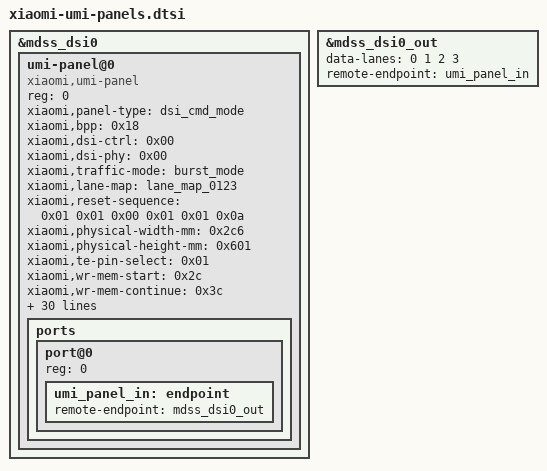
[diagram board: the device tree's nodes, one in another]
// SPDX-License-Identifier: BSD-3-Clause
/*
 * xiaomi-umi-panels.dtsi — 自动生成，别手改
 *   生成: python tools/gen-panel-dts.py dump/panels \
 *             -o dts/xiaomi-umi-panels.dtsi --enable qcom,mdss_dsi_j2_mp_42_02_0b_dsc_cmd
 *
 * 数据全部来自设备自己的下游 DTB。驱动只认 "xiaomi,umi-panel"，
 * 时序 / init 序列 / DSC 参数都从 DT 读 —— 换屏只改 --enable，不用改驱动。
 *
 * ★ 面板节点必须是 &mdss_dsi0 的子节点（reg = <0> 选虚拟通道 0），
 *   否则 mipi_dsi 不会为它创建 mipi_dsi_device，驱动根本不会 probe。
 * ★ 22 个变体不要同时塞进来：同一父节点下只能有一个 panel@0。
 *   换屏 = 重新跑一次生成器 + dtb-only.sh（1 分钟，不用重编内核）。
 */

&mdss_dsi0 {
	umi-panel@0 {
		compatible = "xiaomi,umi-panel";
		reg = <0>;
		status = "okay";
		/* xiaomi,no-init; */
		xiaomi,panel-type = "dsi_cmd_mode";
		xiaomi,bpp = <0x18>;
		xiaomi,dsi-ctrl = <0x00>;
		xiaomi,dsi-phy = <0x00>;
		xiaomi,traffic-mode = "burst_mode";
		xiaomi,lane-map = "lane_map_0123";
		xiaomi,reset-sequence = <0x01 0x01 0x00 0x01 0x01 0x0a>;
		xiaomi,physical-width-mm = <0x2c6>;
		xiaomi,physical-height-mm = <0x601>;
		xiaomi,te-pin-select = <0x01>;
		xiaomi,wr-mem-start = <0x2c>;
		xiaomi,wr-mem-continue = <0x3c>;
		xiaomi,te-dcs-command = <0x01>;
		xiaomi,panel-id = <0x4a32 0x420201>;
		xiaomi,bl-type = "bl_ctrl_dcs";
		xiaomi,bl-min = <0x01>;
		xiaomi,bl-max = <0x7ff>;
		xiaomi,framerate = <0x3c>;
		xiaomi,panel-width = <0x438>;
		xiaomi,panel-height = <0x924>;
		xiaomi,h-front-porch = <0x10>;
		xiaomi,h-back-porch = <0x08>;
		xiaomi,h-pulse-width = <0x08>;
		xiaomi,h-sync-skew = <0x00>;
		xiaomi,v-back-porch = <0x230>;
		xiaomi,v-front-porch = <0x258>;
		xiaomi,v-pulse-width = <0x20>;
		xiaomi,clockrate = <0x28a67e80>;
		xiaomi,on-seq = /bits/ 8 <0x39 0x01 0x00 0x00 0x00 0x00 0x06 0xf0 0x55 0xaa 0x52 0x08 0x07 0x15 0x01 0x00
			0x00 0x00 0x00 0x02 0xc0 0x10 0x39 0x01 0x00 0x00 0x00 0x00 0x06 0xf0 0x55 0xaa
			0x52 0x08 0x03 0x15 0x01 0x00 0x00 0x00 0x00 0x02 0xd4 0x00 0x39 0x01 0x00 0x00
			0x00 0x00 0x06 0xf0 0x55 0xaa 0x52 0x08 0x00 0x15 0x01 0x00 0x00 0x00 0x00 0x02
			0x6f 0x01 0x15 0x01 0x00 0x00 0x00 0x00 0x02 0xb5 0x00 0x15 0x00 0x00 0x00 0x00
			0x00 0x02 0x6f 0x01 0x15 0x00 0x00 0x00 0x00 0x00 0x02 0xc0 0x33 0x39 0x01 0x00
			0x00 0x00 0x00 0x05 0xb2 0x58 0x00 0x08 0x08 0x15 0x00 0x00 0x00 0x00 0x00 0x02
			0x6f 0x01 0x15 0x00 0x00 0x00 0x00 0x00 0x02 0xca 0x30 0x15 0x01 0x00 0x00 0x00
			0x00 0x02 0xb5 0x80 0x15 0x00 0x00 0x00 0x00 0x00 0x02 0x6f 0x01 0x15 0x01 0x00
			0x00 0x00 0x00 0x02 0xc6 0x13 0x39 0x01 0x00 0x00 0x00 0x00 0x06 0xf0 0x55 0xaa
			0x52 0x08 0x01 0x15 0x00 0x00 0x00 0x00 0x00 0x02 0x6f 0x01 0x39 0x01 0x00 0x00
			0x00 0x00 0x07 0xd2 0x00 0x12 0x61 0x25 0x43 0x07 0x39 0x01 0x00 0x00 0x00 0x00
			0x07 0xb7 0x1e 0x1e 0x1e 0x1e 0x1e 0x1e 0x39 0x01 0x00 0x00 0x00 0x00 0x05 0xb8
			0x48 0x48 0x48 0x48 0x15 0x00 0x00 0x00 0x00 0x00 0x02 0x6f 0x01 0x15 0x00 0x00
			0x00 0x00 0x00 0x02 0xb3 0x13 0x15 0x00 0x00 0x00 0x00 0x00 0x02 0x6f 0x01 0x15
			0x01 0x00 0x00 0x00 0x00 0x02 0xb4 0x13 0x39 0x01 0x00 0x00 0x00 0x00 0x03 0xcd
			0x05 0x61 0x39 0x01 0x00 0x00 0x00 0x00 0x06 0xf0 0x55 0xaa 0x52 0x08 0x05 0x39
			0x01 0x00 0x00 0x00 0x00 0x03 0xb3 0x88 0x80 0x39 0x01 0x00 0x00 0x00 0x00 0x03
			0xb5 0x04 0x01 0x39 0x01 0x00 0x00 0x00 0x00 0x05 0xb7 0x04 0x00 0x00 0x01 0x39
			0x01 0x00 0x00 0x00 0x00 0x05 0xb8 0x04 0x00 0x00 0x01 0x39 0x01 0x00 0x00 0x00
			0x00 0x05 0xff 0xaa 0x55 0xa5 0x81 0x15 0x00 0x00 0x00 0x00 0x00 0x02 0x6f 0x0d
			0x15 0x00 0x00 0x00 0x00 0x00 0x02 0xf3 0xab 0x15 0x00 0x00 0x00 0x00 0x00 0x02
			0x6f 0x05 0x39 0x01 0x00 0x00 0x00 0x00 0x03 0xfd 0x00 0xda 0x39 0x01 0x00 0x00
			0x00 0x00 0x05 0xff 0xaa 0x55 0xa5 0x80 0x15 0x00 0x00 0x00 0x00 0x00 0x02 0x6f
			0x0a 0x15 0x01 0x00 0x00 0x00 0x00 0x02 0xfc 0x02 0x15 0x01 0x00 0x00 0x00 0x00
			0x02 0x6f 0x36 0x15 0x01 0x00 0x00 0x00 0x00 0x02 0xf6 0x42 0x39 0x01 0x00 0x00
			0x00 0x00 0x06 0xf0 0x55 0xaa 0x52 0x00 0x00 0x39 0x01 0x00 0x00 0x00 0x00 0x05
			0x3b 0x00 0x0c 0x00 0x04 0x15 0x01 0x00 0x00 0x00 0x00 0x02 0x90 0x01 0x39 0x01
			0x00 0x00 0x00 0x00 0x13 0x93 0x89 0x28 0x00 0x0c 0x02 0x00 0x02 0x0e 0x01 0x1f
			0x00 0x07 0x08 0xbb 0x08 0x7a 0x10 0xf0 0x15 0x01 0x00 0x00 0x00 0x00 0x02 0x03
			0x11 0x05 0x01 0x00 0x00 0x00 0x00 0x02 0x2c 0x00 0x15 0x01 0x00 0x00 0x00 0x00
			0x02 0x35 0x00 0x15 0x01 0x00 0x00 0x00 0x00 0x02 0x53 0x20 0x39 0x01 0x00 0x00
			0x00 0x00 0x05 0x51 0x00 0x00 0x00 0x00 0x39 0x01 0x00 0x00 0x00 0x00 0x05 0x2a
			0x00 0x00 0x04 0x37 0x39 0x01 0x00 0x00 0x00 0x00 0x05 0x2b 0x00 0x00 0x09 0x23
			0x39 0x01 0x00 0x00 0x00 0x00 0x06 0xf0 0x55 0xaa 0x52 0x08 0x00 0x39 0x01 0x00
			0x00 0x00 0x00 0x1e 0xb4 0xcb 0xbb 0xbb 0xaa 0x99 0x77 0x66 0x00 0x00 0x00 0xb4
			0xd0 0xd0 0xd0 0xd0 0xd0 0x86 0x86 0x3c 0x3c 0xf2 0xf2 0xa8 0xa8 0x36 0x36 0x36
			0x36 0x0a 0x15 0x01 0x00 0x00 0x00 0x00 0x02 0x2f 0x01 0x15 0x01 0x00 0x00 0x00
			0x00 0x02 0x26 0x01 0x05 0x01 0x00 0x00 0x64 0x00 0x02 0x11 0x00 0x05 0x01 0x00
			0x00 0x00 0x00 0x02 0x29 0x00 0x39 0x01 0x00 0x00 0x00 0x00 0x06 0xf0 0x55 0xaa
			0x52 0x08 0x00 0x15 0x01 0x00 0x00 0x00 0x00 0x02 0xb5 0x84>;
		xiaomi,off-seq = /bits/ 8 <0x05 0x01 0x00 0x00 0x00 0x00 0x02 0x28 0x00 0x05 0x01 0x00 0x00 0x78 0x00 0x02
			0x10 0x00>;
		xiaomi,compression = "dsc";
		xiaomi,dsc-version = <0x11>;
		xiaomi,dsc-slice-height = <0x0c>;
		xiaomi,dsc-slice-width = <0x21c>;
		xiaomi,dsc-slice-per-pkt = <0x02>;
		xiaomi,dsc-bpc = <0x08>;
		xiaomi,dsc-bpp = <0x08>;
		xiaomi,dsc-block-prediction;
		xiaomi,phy-timings = [00 18 06 06 21 20 06 06 04 02 04 00 15 16];

		ports {
			#address-cells = <1>;
			#size-cells = <0>;

			port@0 {
				reg = <0>;

				umi_panel_in: endpoint {
					remote-endpoint = <&mdss_dsi0_out>;
				};
			};
		};
	};
};

&mdss_dsi0_out {
	data-lanes = <0 1 2 3>;	/* 下游 lane-0..3-state 全开 => 4 lane DPHY */
	remote-endpoint = <&umi_panel_in>;
};
